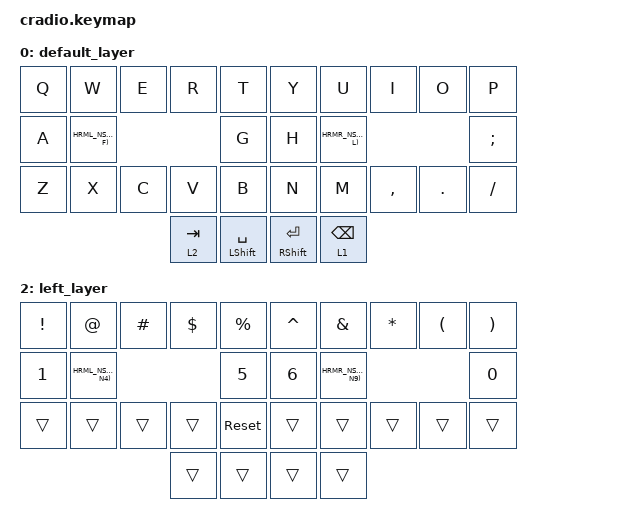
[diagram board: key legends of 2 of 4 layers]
// Copyright (c) 2022 The ZMK Contributors
// SPDX-License-Identifier: MIT

#include <behaviors.dtsi>
#include <dt-bindings/zmk/keys.h>
#include <dt-bindings/zmk/bt.h>

// Home row mods macro
#define HRML(k1,k2,k3,k4) &ht LSHFT k1  &ht LALT k2  &ht LCTRL k3  &ht LGUI k4
#define HRMR(k1,k2,k3,k4) &ht RGUI k1  &ht RCTRL k2  &ht RALT k3  &ht RSHFT k4

// Home row mods macro without shift
#define HRML_NS(k1,k2,k3) &ht LALT k1  &ht LCTRL k2  &ht LGUI k3
#define HRMR_NS(k1,k2,k3) &ht RGUI k1  &ht RCTRL k2  &ht RALT k3

/ {
    behaviors {
        ht: hold_tap {
            compatible = "zmk,behavior-hold-tap";
            #binding-cells = <2>;
            flavor = "tap-preferred";
            tapping-term-ms = <220>;
            quick-tap-ms = <150>;
            require-prior-idle-ms = <100>;
            bindings = <&kp>, <&kp>;
        };
    };

    conditional_layers {
        compatible = "zmk,conditional-layers";
        tri_layer {
            if-layers = <1 2>;
            then-layer = <3>;
        };
    };

    keymap {
        compatible = "zmk,keymap";
        default_layer {
            bindings = <
        //╭───────────────┬───────────────┬───────────────┬───────────────┬──────────────────╮   ╭──────────────────┬───────────────┬───────────────┬───────────────┬───────────────╮
        //│ Q             │ W             │ E             │ R             │ T                │   │ Y                │ U             │ I             │ O             │ P             │
            &kp Q           &kp W           &kp E           &kp R           &kp T                  &kp Y              &kp U           &kp I           &kp O           &kp P
        //├───────────────┼───────────────┼───────────────┼───────────────┼──────────────────┤   ├──────────────────┼───────────────┼───────────────┼───────────────┼───────────────┤
        //│ A             │ S             │ D             │ F             │ G                │   │ H                │ J             │ K             │ L             │ ; :           │
            &kp A           HRML_NS(S,      D,              F)              &kp G                  &kp H              HRMR_NS(J,      K,              L)              &kp SEMI
        //├───────────────┼───────────────┼───────────────┼───────────────┼──────────────────┤   ├──────────────────┼───────────────┼───────────────┼───────────────┼───────────────┤
        //│ Z             │ X             │ C             │ V             │ B                │   │ N                │ M             │ , <           │ . >           │ / ?           │
            &kp Z           &kp X           &kp C           &kp V           &kp B                  &kp N              &kp M           &kp COMMA       &kp DOT         &kp FSLH
        //╰───────────────┴───────────────┴───────────────┼───────────────┼──────────────────┤   ├──────────────────┼───────────────┼───────────────┴───────────────┴───────────────╯
        //                                                │               │                  │   │                  │               │
                                                            &lt 2 TAB       &ht LSHIFT SPACE       &ht RSHIFT ENTER   &lt 1 BSPC
        //                                                ╰───────────────┴──────────────────╯   ╰──────────────────┴───────────────╯
            >;
	};

	right_layer {
            bindings = <
        //╭───────────────┬───────────────┬───────────────┬───────────────┬───────────────╮   ╭───────────────┬───────────────┬───────────────┬───────────────┬───────────────╮
        //│ |             │ \ |           │ (             │ )             │ ~             │   │ INSERT        │ HOME          │ END           │ PAGE UP       │ PAGE DN       │
            &kp PIPE        &kp BSLH        &kp LPAR        &kp RPAR        &kp TILDE           &kp INS         &kp HOME        &kp END         &kp PG_UP       &kp PG_DN
        //├───────────────┼───────────────┼───────────────┼───────────────┼───────────────┤   ├───────────────┼───────────────┼───────────────┼───────────────┼───────────────┤
        //│ _             │ -             │ [             │ ]             │ `             │   │ LEFT          │ DOWN          │ UP            │ RIGHT         │ ESCAPE        │
            &kp UNDER       HRML_NS(MINUS,  LBKT,           RBKT)           &kp GRAVE           &kp LEFT        &kp DOWN        &kp UP          &kp RIGHT       &kp ESC
        //├───────────────┼───────────────┼───────────────┼───────────────┼───────────────┤   ├───────────────┼───────────────┼───────────────┼───────────────┼───────────────┤
        //│ +             │ =             │ {             │ }             │               │   │ RESET         │ BACKSPACE     │ DELETE        │ ' "           │ "             │
            &kp PLUS        &kp EQUAL       &kp LBRC        &kp RBRC        &trans              &sys_reset      &kp BSPC        &kp DEL         &kp SQT         &kp DQT
        //╰───────────────┴───────────────┴───────────────┼───────────────┼───────────────┤   ├───────────────┼───────────────┼───────────────┴───────────────┴───────────────╯
        //                                                │               │               │   │               │               │
                                                            &trans          &trans              &trans          &trans
        //                                                ╰───────────────┴───────────────╯   ╰───────────────┴───────────────╯
            >;
        };

        left_layer {
            bindings = <
        //╭───────────────┬───────────────┬───────────────┬───────────────┬───────────────╮   ╭───────────────┬───────────────┬───────────────┬───────────────┬───────────────╮
        //│ !             │ @             │ #             │ $             │ %             │   │ ^             │ &             │ *             │ (             │ )             │
            &kp EXCL        &kp AT          &kp HASH        &kp DLLR        &kp PRCNT           &kp CARET       &kp AMPS        &kp ASTRK       &kp LPAR        &kp RPAR
        //├───────────────┼───────────────┼───────────────┼───────────────┼───────────────┤   ├───────────────┼───────────────┼───────────────┼───────────────┼───────────────┤
        //│ 1             │ 2             │ 3             │ 4             │ 5             │   │ 6             │ 7             │ 8             │ 9             │ 0             │
            &kp N1          HRML_NS(N2,     N3,             N4)             &kp N5              &kp N6          HRMR_NS(N7,     N8,             N9)             &kp N0
        //├───────────────┼───────────────┼───────────────┼───────────────┼───────────────┤   ├───────────────┼───────────────┼───────────────┼───────────────┼───────────────┤
        //│               │               │               │               │ RESET         │   │               │               │               │               │               │
            &trans          &trans          &trans          &trans          &sys_reset          &trans          &trans          &trans          &trans          &trans
        //╰───────────────┴───────────────┴───────────────┼───────────────┼───────────────┤   ├───────────────┼───────────────┼───────────────┴───────────────┴───────────────╯
        //                                                │               │               │   │               │               │
                                                            &trans          &trans              &trans          &trans
        //                                                ╰───────────────┴───────────────╯   ╰───────────────┴───────────────╯
            >;
        };

        tri_layer {
            bindings = <
        //╭───────────────┬───────────────┬───────────────┬───────────────┬───────────────╮   ╭───────────────┬───────────────┬───────────────┬───────────────┬───────────────╮
        //│               │ PROFILE 0     │ PROFILE 1     │ PROFILE 2     │ CLEAR BT      │   │ CAPS          │               │               │ ZMK Studio    │               │
            &trans          &bt BT_SEL 0    &bt BT_SEL 1    &bt BT_SEL 2    &bt BT_CLR          &caps_word      &trans          &trans          &studio_unlock  &trans
        //├───────────────┼───────────────┼───────────────┼───────────────┼───────────────┤   ├───────────────┼───────────────┼───────────────┼───────────────┼───────────────┤
        //│ BOOTLOADER    │               │               │               │ F11           │   │ F12           │               │               │               │ BOOTLOADER    │
            &bootloader     &trans          &trans          &trans          &kp F11             &kp F12         &trans          &trans          &trans          &bootloader
        //├───────────────┼───────────────┼───────────────┼───────────────┼───────────────┤   ├───────────────┼───────────────┼───────────────┼───────────────┼───────────────┤
        //│ F1            │ F2            │ F3            │ F4            │ F5            │   │ F6            │ F7            │ F8            │ F9            │ F10           │
            &kp F1          &kp F2          &kp F3          &kp F4          &kp F5              &kp F6          &kp F7          &kp F8          &kp F9          &kp F10
        //╰───────────────┴───────────────┴───────────────┼───────────────┼───────────────┤   ├───────────────┼───────────────┼───────────────┴───────────────┴───────────────╯
        //                                                │               │               │   │               │               │
                                                            &trans          &trans              &trans          &trans
        //                                                ╰───────────────┴───────────────╯   ╰───────────────┴───────────────╯
            >;
        };

        extra1 {
            status = "reserved";
        };

        extra2 {
            status = "reserved";
        };
    };
};
